# DISPC register map
Vendor: Texas Instruments
Registers are 32-bit, access per field, reset 0x0 unless marked. A register's access mark holds for its fields unless they carry their own. Offsets are as the file gives them; [hi:lo] are bit positions; {n}, {i} and the like mark numbered series; 'fields as' and 'values as' point back to an identical list.

## DISPC (part 6 of 6)
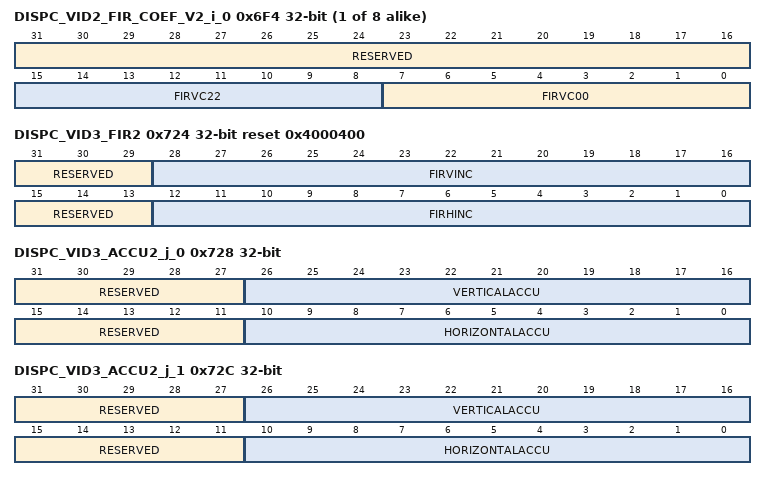
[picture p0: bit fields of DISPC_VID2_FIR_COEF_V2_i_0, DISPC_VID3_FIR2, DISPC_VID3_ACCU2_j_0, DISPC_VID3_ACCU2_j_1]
{0x6F4+4i} DISPC_VID2_FIR_COEF_V2_i_{i} (i=0..7) — The bank of registers configure the down/up/down-scaling coefficients for the vertical resize of the video picture associated with the video window 2 for the phases from 0 to 7. It is used for Crb and Cr setting. It is used only when the pixel format at the input of the filter is one of the YUV formats. If the pixel format at the input of the filter is ARGB (all ARGB, RGB, RGBA are converted to ARGB32-8888 by the color space conversion before going to the filter is the color space conversion is done before the filter). When the register is not used by the hardware, any value can be used for the bit fields. Shadow register, updated on VFP start period of primary LCD or VFP start period of the secondary LCD or VFP start period of the third LCD or EVSYNC or when.GOWB is set to 1 by software and current WB frame is finished (no more data in the write-back pipeline). The synchronization event is defined based on the output using the pipeline: primary LCD, secondary LCD, third LCD, TV output or write-back to the memory
  [31:16] RESERVED ro — Write 0s for future compatibility. Reads return 0.
  [15:8] FIRVC22 rw — Signed coefficient C22 for the vertical up/down-scaling with the phase n
  [7:0] FIRVC00 rw — Signed coefficient C00 for the vertical up/down-scaling with the phase n
0x724 DISPC_VID3_FIR2 reset 0x4000400 — The register configures the resize factors for horizontal and vertical up/downsampling of the video window 3. It is used for Crb and Cr setting. It is used only when the pixel format at the input of the filter is one of the YUV formats. If the pixel format at the input of the filter is ARGB (all ARGB, RGB, RGBA are converted to ARGB32-8888 by the color space conversion before going to the filter is the color space conversion is done before the filter). When the register is not used by the hardware, any value can be used for the bit fields. Shadow register, updated on VFP start period of primary LCD or VFP start period of the secondary LCD or VFP start period of the third LCD or EVSYNC or when.GOWB is set to 1 by software and current WB frame is finished (no more data in the write-back pipeline). The synchronization event is defined based on the output using the pipeline: primary LCD, secondary LCD, third LCD, TV output or write-back to the memory
  [31:29] RESERVED ro — Write 0s for future compatibility. Reads return 0.
  [28:16] FIRVINC rw — Vertical increment of the up/downsampling filter for Cb and Cr. Encoded value (from 1 to 4096). The value 0 is invalid. The values greater than 4096 are invalid.
  [15:13] RESERVED ro — Write 0s for future compatibility. Reads return 0.
  [12:0] FIRHINC rw — Horizontal increment of the up/downsampling filter for Cb and Cr. Encoded value (from 1 to 4096). The value 0 is invalid. The values greater than 4096 are invalid.
0x728 DISPC_VID3_ACCU2_j_0 — The register configures the resize accumulator init values for horizontal and vertical up/downsampling of the video window 3 (DISPC_VID3_ACCU2_0 and DISPC_VID3_ACCU2_1 for ping-pong mechanism with external trigger, based on the field polarity). It is used for Cb and Cr setting. It is used only when the pixel format at the input of the filter is one of the YUV formats. If the pixel format at the input of the filter is ARGB (all ARGB, RGB, RGBA are converted to ARGB32-8888 by the color space conversion before going to the filter is the color space conversion is done before the filter). When the register is not used by the hardware, any value can be used for the bit fields. Shadow register, updated on VFP start period of primary LCD or VFP start period of the secondary LCD or VFP start period of the third LCD or EVSYNC or when.GOWB is set to 1 by software and current WB frame is finished (no more data in the write-back pipeline). The synchronization event is defined based on the output using the pipeline: primary LCD, secondary LCD, third LCD, TV output or write-back to the memory
  [31:27] RESERVED ro — Write 0s for future compatibility. Reads return 0.
  [26:16] VERTICALACCU rw — Vertical initialization accu value Encoded value (from –1024 to 1023).
  [15:11] RESERVED ro — Write 0s for future compatibility. Reads return 0.
  [10:0] HORIZONTALACCU rw — Horizontal initialization accu value Encoded value (from –1024 to 1023).
0x72C DISPC_VID3_ACCU2_j_1 — The register configures the resize accumulator init values for horizontal and vertical up/downsampling of the video window 3 (DISPC_VID3_ACCU2_0 and DISPC_VID3_ACCU2_1 for ping-pong mechanism with external trigger, based on the field polarity). It is used for Cb and Cr setting. It is used only when the pixel format at the input of the filter is one of the YUV formats. If the pixel format at the input of the filter is ARGB (all ARGB, RGB, RGBA are converted to ARGB32-8888 by the color space conversion before going to the filter is the color space conversion is done before the filter). When the register is not used by the hardware, any value can be used for the bit fields. Shadow register, updated on VFP start period of primary LCD or VFP start period of the secondary LCD or VFP start period of the third LCD or EVSYNC or when.GOWB is set to 1 by software and current WB frame is finished (no more data in the write-back pipeline). The synchronization event is defined based on the output using the pipeline: primary LCD, secondary LCD, third LCD, TV output or write-back to the memory
  fields as DISPC_VID3_ACCU2_j_0
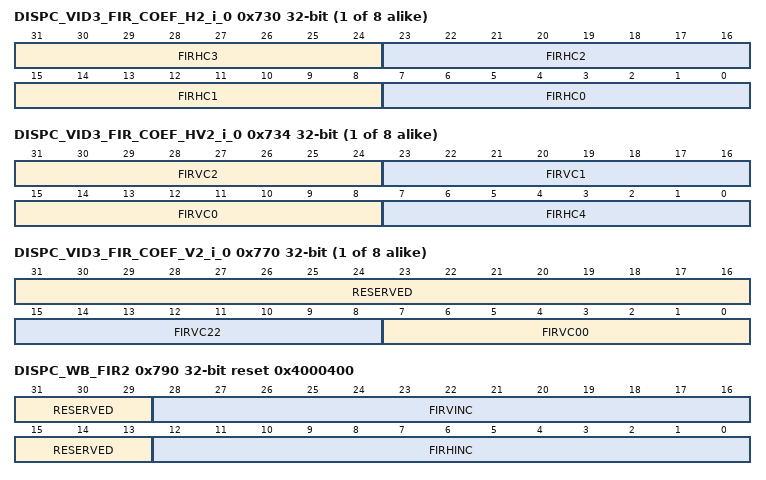
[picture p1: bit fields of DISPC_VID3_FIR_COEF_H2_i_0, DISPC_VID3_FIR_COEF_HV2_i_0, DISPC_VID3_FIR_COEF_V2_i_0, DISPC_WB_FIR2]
{0x730+8i} DISPC_VID3_FIR_COEF_H2_i_{i} rw (i=0..7) — The bank of registers configure the up/down-scaling coefficients for the horizontal resize of the video picture associated with the video window 3 for the phases from 0 to 7. It is used for Crb and Cr setting. It is used only when the pixel format at the input of the filter is one of the YUV formats. If the pixel format at the input of the filter is ARGB (all ARGB, RGB, RGBA are converted to ARGB32-8888 by the color space conversion before going to the filter is the color space conversion is done before the filter). When the register is not used by the hardware, any value can be used for the bit fields. Shadow register, updated on VFP start period of primary LCD or VFP start period of the secondary LCD or VFP start period of the third LCD or EVSYNC or when.GOWB is set to 1 by software and current WB frame is finished (no more data in the write-back pipeline). The synchronization event is defined based on the output using the pipeline: primary LCD, secondary LCD, third LCD, TV output or write-back to the memory
  [31:24] FIRHC3 — Signed coefficient C3 for the horizontal up/down-scaling with the phase n
  [23:16] FIRHC2 — Unsigned coefficient C2 for the horizontal up/down-scaling with the phase n
  [15:8] FIRHC1 — Signed coefficient C1 for the horizontal up/down-scaling with the phase n
  [7:0] FIRHC0 — Signed coefficient C0 for the horizontal up/down-scaling with the phase n
{0x734+8i} DISPC_VID3_FIR_COEF_HV2_i_{i} rw (i=0..7) — The bank of registers configure the down/up/down-scaling coefficients for the vertical and horizontal resize of the video picture associated with the video window 3 for the phases from 0 to 7. It is used for Crb and Cr setting. It is used only when the pixel format at the input of the filter is one of the YUV formats. If the pixel format at the input of the filter is ARGB (all ARGB, RGB, RGBA are converted to ARGB32-8888 by the color space conversion before going to the filter is the color space conversion is done before the filter). When the register is not used by the hardware, any value can be used for the bit fields. Shadow register, updated on VFP start period of primary LCD or VFP start period of the secondary LCD or VFP start period of the third LCD or EVSYNC or when.GOWB is set to 1 by software and current WB frame is finished (no more data in the write-back pipeline). The synchronization event is defined based on the output using the pipeline: primary LCD, secondary LCD, third LCD, TV output or write-back to the memory
  [31:24] FIRVC2 — Signed coefficient C2 for the vertical up/down-scaling with the phase n
  [23:16] FIRVC1 — Unsigned coefficient C1 for the vertical up/down-scaling with the phase n
  [15:8] FIRVC0 — Signed coefficient C0 for the vertical up/down-scaling with the phase n
  [7:0] FIRHC4 — Signed coefficient C4 for the horizontal up/down-scaling with the phase n
{0x770+4i} DISPC_VID3_FIR_COEF_V2_i_{i} (i=0..7) — The bank of registers configure the down/up/down-scaling coefficients for the vertical resize of the video picture associated with the video window 3 for the phases from 0 to 7. It is used for Crb and Cr setting. It is used only when the pixel format at the input of the filter is one of the YUV formats. If the pixel format at the input of the filter is ARGB (all ARGB, RGB, RGBA are converted to ARGB32-8888 by the color space conversion before going to the filter is the color space conversion is done before the filter). When the register is not used by the hardware, any value can be used for the bit fields. Shadow register, updated on VFP start period of primary LCD or VFP start period of the secondary LCD or VFP start period of the third LCD or EVSYNC or when.GOWB is set to 1 by software and current WB frame is finished (no more data in the write-back pipeline). The synchronization event is defined based on the output using the pipeline: primary LCD, secondary LCD, third LCD, TV output or write-back to the memory
  fields as DISPC_VID2_FIR_COEF_V2_i_0
0x790 DISPC_WB_FIR2 reset 0x4000400 — The register configures the resize factors for horizontal and vertical up/downsampling of the write-back pipeline. It is used for Crb and Cr setting. It is used only when the pixel format at the input of the filter is one of the YUV formats. If the pixel format at the input of the filter is ARGB (all ARGB, RGB, RGBA are converted to ARGB32-8888 by the color space conversion before going to the filter is the color space conversion is done before the filter). When the register is not used by the hardware, any value can be used for the bit fields. Shadow register, updated when.GOWB is set to 1 by software and current WB frame is finished (no more data in the write-back pipeline), when the WB pipeline is directly connected to one of the pipelines (graphics or video), combined with the synchronization event of the channel overlay output selected as an input to the WB pipeline (that is, VFP start period of primary LCD, or VFP start period of secondary LCD, or VFP start period of the third LCD, or EVSYNC), for all registers associated with the selected channel out and further delayed by the .WBDELAYCOUNT bit-field, for all registers of the Write back and DMA. In WB capture mode, both .GOWB and DISPC_CONTROL#.GOLCD/TV corresponding to the selected output channel shall be set. It is not required to set the GOWB bit when WB memory-to-memory mode is used.
  fields as DISPC_VID3_FIR2
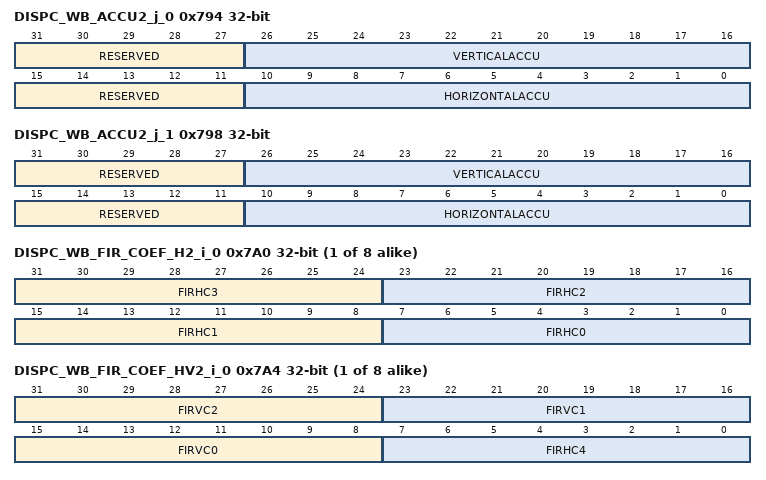
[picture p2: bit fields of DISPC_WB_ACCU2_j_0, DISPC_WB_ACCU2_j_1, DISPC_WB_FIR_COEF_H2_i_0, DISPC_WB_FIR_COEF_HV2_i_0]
0x794 DISPC_WB_ACCU2_j_0 — The register configures the resize accumulator init values for horizontal and vertical up/downsampling of the write back pipeline (DISPC_WB_ACCU2_0 and DISPC_WB_ACCU2_1 for ping-pong mechanism with external trigger, based on the field polarity). It is used for Cb and Cr setting. It is used only when the pixel format at the input of the filter is one of the YUV formats. If the pixel format at the input of the filter is ARGB (all ARGB, RGB, RGBA are converted to ARGB32-8888 by the color space conversion before going to the filter is the color space conversion is done before the filter). When the register is not used by the hardware, any value can be used for the bit fields. Shadow register, updated when.GOWB is set to 1 by software and current WB frame is finished (no more data in the write-back pipeline), when the WB pipeline is directly connected to one of the pipelines (graphics or video), combined with the synchronization event of the channel overlay output selected as an input to the WB pipeline (that is, VFP start period of primary LCD, or VFP start period of secondary LCD, or VFP start period of the third LCD, or EVSYNC), for all registers associated with the selected channel out and further delayed by the .WBDELAYCOUNT bit-field, for all registers of the Write back and DMA. In WB capture mode, both .GOWB and DISPC_CONTROL#.GOLCD/TV corresponding to the selected output channel shall be set. It is not required to set the GOWB bit when WB memory-to-memory mode is used.
  fields as DISPC_VID3_ACCU2_j_0
0x798 DISPC_WB_ACCU2_j_1 — The register configures the resize accumulator init values for horizontal and vertical up/downsampling of the write back pipeline (DISPC_WB_ACCU2_0 and DISPC_WB_ACCU2_1 for ping-pong mechanism with external trigger, based on the field polarity). It is used for Cb and Cr setting. It is used only when the pixel format at the input of the filter is one of the YUV formats. If the pixel format at the input of the filter is ARGB (all ARGB, RGB, RGBA are converted to ARGB32-8888 by the color space conversion before going to the filter is the color space conversion is done before the filter). When the register is not used by the hardware, any value can be used for the bit fields. Shadow register, updated when.GOWB is set to 1 by software and current WB frame is finished (no more data in the write-back pipeline), when the WB pipeline is directly connected to one of the pipelines (graphics or video), combined with the synchronization event of the channel overlay output selected as an input to the WB pipeline (that is, VFP start period of primary LCD, or VFP start period of secondary LCD, or VFP start period of the third LCD, or EVSYNC), for all registers associated with the selected channel out and further delayed by the .WBDELAYCOUNT bit-field, for all registers of the Write back and DMA. In WB capture mode, both .GOWB and DISPC_CONTROL#.GOLCD/TV corresponding to the selected output channel shall be set. It is not required to set the GOWB bit when WB memory-to-memory mode is used.
  fields as DISPC_VID3_ACCU2_j_0
{0x7A0+8i} DISPC_WB_FIR_COEF_H2_i_{i} rw (i=0..7) — The bank of registers configure the up/down-scaling coefficients for the horizontal resize of the video picture associated with the write back pipeline for the phases from 0 to 7. It is used for Crb and Cr setting. It is used only when the pixel format at the input of the filter is one of the YUV formats. If the pixel format at the input of the filter is ARGB (all ARGB, RGB, RGBA are converted to ARGB32-8888 by the color space conversion before going to the filter is the color space conversion is done before the filter). When the register is not used by the hardware, any value can be used for the bit fields. Shadow register, updated when.GOWB is set to 1 by software and current WB frame is finished (no more data in the write-back pipeline), when the WB pipeline is directly connected to one of the pipelines (graphics or video), combined with the synchronization event of the channel overlay output selected as an input to the WB pipeline (that is, VFP start period of primary LCD, or VFP start period of secondary LCD, or VFP start period of the third LCD, or EVSYNC), for all registers associated with the selected channel out and further delayed by the .WBDELAYCOUNT bit-field, for all registers of the Write back and DMA. In WB capture mode, both .GOWB and DISPC_CONTROL#.GOLCD/TV corresponding to the selected output channel shall be set. It is not required to set the GOWB bit when WB memory-to-memory mode is used.
  fields as DISPC_VID3_FIR_COEF_H2_i_0
{0x7A4+8i} DISPC_WB_FIR_COEF_HV2_i_{i} rw (i=0..7) — The bank of registers configure the down/up/down-scaling coefficients for the vertical and horizontal resize of the video picture associated with the write back pipeline for the phases from 0 to 7. It is used for Crb and Cr setting. It is used only when the pixel format at the input of the filter is one of the YUV formats. If the pixel format at the input of the filter is ARGB (all ARGB, RGB, RGBA are converted to ARGB32-8888 by the color space conversion before going to the filter is the color space conversion is done before the filter). When the register is not used by the hardware, any value can be used for the bit fields. Shadow register, updated when.GOWB is set to 1 by software and current WB frame is finished (no more data in the write-back pipeline), when the WB pipeline is directly connected to one of the pipelines (graphics or video), combined with the synchronization event of the channel overlay output selected as an input to the WB pipeline (that is, VFP start period of primary LCD, or VFP start period of secondary LCD, or VFP start period of the third LCD, or EVSYNC), for all registers associated with the selected channel out and further delayed by the .WBDELAYCOUNT bit-field, for all registers of the Write back and DMA. In WB capture mode, both .GOWB and DISPC_CONTROL#.GOLCD/TV corresponding to the selected output channel shall be set. It is not required to set the GOWB bit when WB memory-to-memory mode is used.
  fields as DISPC_VID3_FIR_COEF_HV2_i_0
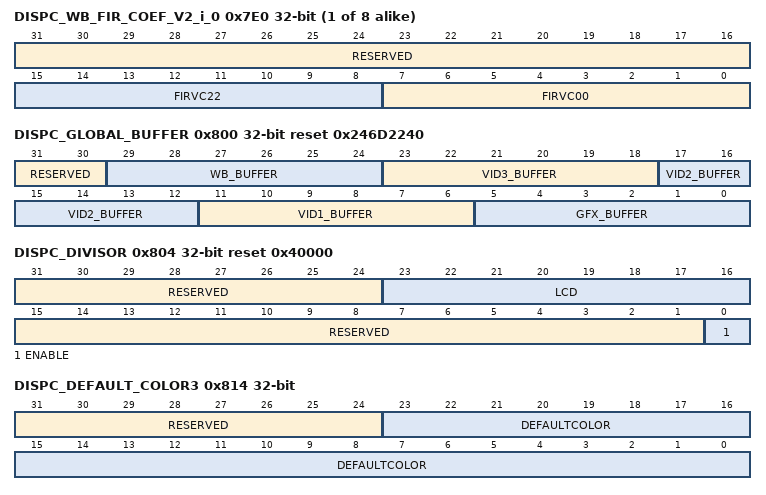
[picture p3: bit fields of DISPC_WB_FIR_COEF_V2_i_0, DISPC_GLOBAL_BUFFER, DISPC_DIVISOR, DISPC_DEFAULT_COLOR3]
{0x7E0+4i} DISPC_WB_FIR_COEF_V2_i_{i} (i=0..7) — The bank of registers configure the down/up/down-scaling coefficients for the vertical resize of the video picture associated with the write back pipeline for the phases from 0 to 7. It is used for Crb and Cr setting. It is used only when the pixel format at the input of the filter is one of the YUV formats. If the pixel format at the input of the filter is ARGB (all ARGB, RGB, RGBA are converted to ARGB32-8888 by the color space conversion before going to the filter is the color space conversion is done before the filter). When the register is not used by the hardware, any value can be used for the bit fields. Shadow register, updated when.GOWB is set to 1 by software and current WB frame is finished (no more data in the write-back pipeline), when the WB pipeline is directly connected to one of the pipelines (graphics or video), combined with the synchronization event of the channel overlay output selected as an input to the WB pipeline (that is, VFP start period of primary LCD, or VFP start period of secondary LCD, or VFP start period of the third LCD, or EVSYNC), for all registers associated with the selected channel out and further delayed by the .WBDELAYCOUNT bit-field, for all registers of the Write back and DMA. In WB capture mode, both .GOWB and DISPC_CONTROL#.GOLCD/TV corresponding to the selected output channel shall be set. It is not required to set the GOWB bit when WB memory-to-memory mode is used.
  fields as DISPC_VID2_FIR_COEF_V2_i_0
0x800 DISPC_GLOBAL_BUFFER reset 0x246D2240 — The register configures the DMA buffers allocations to the pipeline (graphics, video1, video2, video3 and write-back). Both TOP and BOTTOM must be allocated to the same pipeline.
  [31:30] RESERVED ro — Write 0's for future compatibility. Reads return 0
  [29:24] WB_BUFFER rw — Write-back DMA buffer allocation to one of the pipelines. By default to write-back pipeline.
    36=Wb (DMA buffer allocated to the write-back pipeline.); 0=Gfx (DMA buffer allocated to the graphics pipeline.); 9=Vid1 (DMA buffer allocated to the video1 pipeline.); 18=Vid2 (DMA buffer allocated to the vdieo2 pipeline.); 27=Vid3 (DMA buffer allocated to the vdieo3 pipeline.)
  [23:18] VID3_BUFFER rw — Video3 DMA buffer allocation to one of the pipelines. By default to video3 pipeline.
    values as WB_BUFFER
  [17:12] VID2_BUFFER rw — Video2 DMA buffer allocation to one of the pipelines. By default to video2 pipeline.
    values as WB_BUFFER
  [11:6] VID1_BUFFER rw — Video1 DMA buffer allocation to one of the pipelines. By default to video 1 pipeline.
    values as WB_BUFFER
  [5:0] GFX_BUFFER rw — Graphics DMA buffer allocation to one of the pipelines. By default to graphics pipeline.
    values as WB_BUFFER
0x804 DISPC_DIVISOR reset 0x40000 — The register configures the divisor value for generating the core functional clock. There is a backward compatibility mode enabled by default in order to use.LCD value instead of .LCD bit field for generating the core functional clock.
  [31:24] RESERVED ro — Write 0s for future compatibility. Reads return 0.
  [23:16] LCD rw — Display Controller Logic Clock Divisor Value (from 1 to 255) to specify the frequency of the Display Controller logic clock based on the function clock. The value 0 is invalid.
  [15:1] RESERVED ro — Write 0s for future compatibility. Reads return 0.
  [0] ENABLE rw — When the bit field is set to 1, the bit field LCD is used to generated the core functional clock from the input clock. When the bit field is set to 0, the valueDISPC_DIVISOR1.LCD is used instead.
    0=Disable (.LCD bit field is used); 1=Enable (.LCD bit field is used)
0x810 DISPC_WB_ATTRIBUTES2 — The register set the counter to control the delay to flush the WB pipe after the end of the frame in capture mode. Shadow register, updated when .GOWB is set to 1 by software and current WB frame is finished (no more data in the write-back pipeline), when the WB pipeline is directly connected to one of the pipelines (graphics or video), combined with the synchronization event of the channel overlay output selected as an input to the WB pipeline (that is, VFP start period of primary LCD, or VFP start period of secondary LCD, or VFP start period of the third LCD, or EVSYNC), for all registers associated with the selected channel out and further delayed by the .WBDELAYCOUNT bit-field, for all registers of the Write back and DMA. In WB capture mode, both .GOWB and DISPC_CONTROL#.GOLCD/TV corresponding to the selected output channel shall be set. It is not required to set the GOWB bit when WB memory-to-memory mode is used.
  [7:0] WBDELAYCOUNT rw — Delays the WB pipe flush after the end of the frame. Delay = n (number of lines), where n = 0:255. If n = 0, the WB is re-initialized just at the end of the last line of a frame at the beginning of the VFP signal. If n = 1:255, the write buffers DMA are flushed n lines later.
0x814 DISPC_DEFAULT_COLOR3 — The control register allows to configure the default solid background color for the third LCD. Shadow register, updated on VFP start period of third LCD
  [31:24] RESERVED ro — Write 0s for future compatibility. Reads return 0.
  [23:0] DEFAULTCOLOR rw — 24-bit RGB color value to specify the default solid color to display when there is no data from the overlays
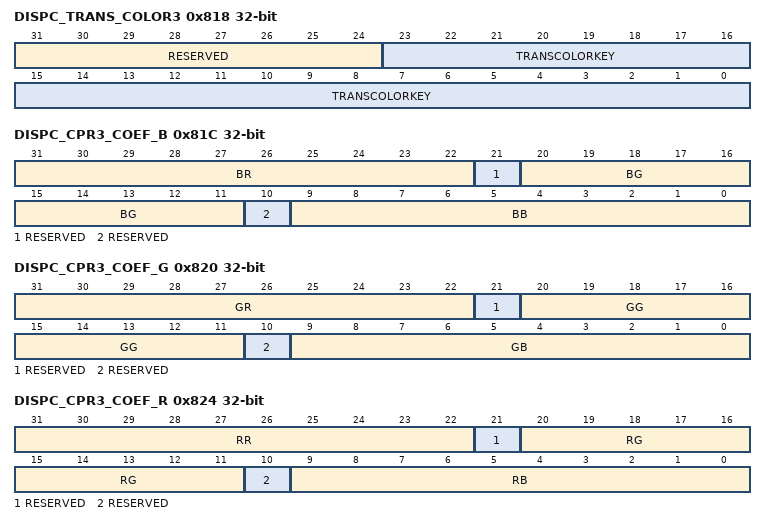
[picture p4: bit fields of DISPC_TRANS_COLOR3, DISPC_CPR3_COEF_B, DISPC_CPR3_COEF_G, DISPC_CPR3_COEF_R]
0x818 DISPC_TRANS_COLOR3 — The register sets the transparency color value for the video/graphics overlays for the third LCD output. Shadow register, updated on VFP start period of the third LCD
  [31:24] RESERVED ro — Write 0s for future compatibility. Reads return 0.
  [23:0] TRANSCOLORKEY rw — Transparency color key value in RGB format [0] BITMAP 1 (CLUT), [23,1] set to 0s [1:0] BITMAP 2 (CLUT), [23,2] set to 0s [3:0] BITMAP 4 (CLUT), [23,4] set to 0s [7:0] BITMAP 8 (CLUT), [23,8] set to 0s [11:0] RGB 12, [23,12] set to 0s [15:0] RGB 16, [23,16] set to 0s [23:0] RGB 24 NOTE: CLUT and BITMAP formats are not supported in this family of devices.
0x81C DISPC_CPR3_COEF_B — The register configures the color phase rotation matrix coefficients for the blue component. It is used for the secondary LCD output. Shadow register, updated on VFP start period of third LCD
  [31:22] BR rw — BR coefficient Encoded signed value (from –512 to 511)
  [21] RESERVED ro — Write 0s for future compatibility. Reads return 0.
  [20:11] BG rw — BG coefficient Encoded signed value (from –512 to 511)
  [10] RESERVED ro — Write 0s for future compatibility. Reads return 0.
  [9:0] BB rw — BB coefficient Encoded signed value (from –512 to 511)
0x820 DISPC_CPR3_COEF_G — The register configures the color phase rotation matrix coefficients for the green component. It is used for the secondary LCD output. Shadow register, updated on VFP start period of third LCD
  [31:22] GR rw — GRcoefficient Encoded signed value (from –512 to 511)
  [21] RESERVED ro — Write 0s for future compatibility. Reads return 0.
  [20:11] GG rw — GG coefficient Encoded signed value (from –512 to 511)
  [10] RESERVED ro — Write 0s for future compatibility. Reads return 0.
  [9:0] GB rw — GB coefficient Encoded signed value (from –512 to 511)
0x824 DISPC_CPR3_COEF_R — The register configures the color phase rotation matrix coefficients for the red component. Shadow register, updated on VFP start period of third LCD
  [31:22] RR rw — RR coefficient Encoded signed value (from –512 to 511)
  [21] RESERVED ro — Write 0s for future compatibility. Reads return 0.
  [20:11] RG rw — RG coefficient Encoded signed value (from –512 to 511)
  [10] RESERVED ro — Write 0s for future compatibility. Reads return 0.
  [9:0] RB rw — RB coefficient Encoded signed value (from –512 to 511)
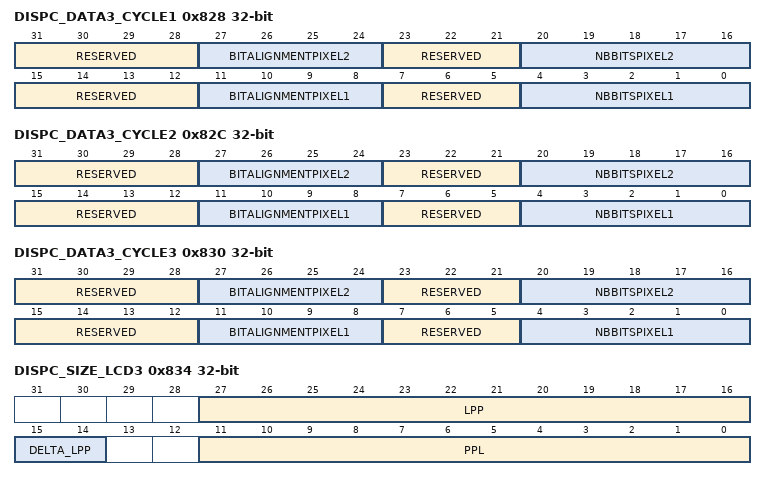
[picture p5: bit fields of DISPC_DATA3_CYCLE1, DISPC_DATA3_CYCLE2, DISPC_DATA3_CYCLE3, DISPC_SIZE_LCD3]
0x828 DISPC_DATA3_CYCLE1 — The control register configures the output data format for the first cycle. Shadow register, updated on VFP start period of third LCD
  [31:28] RESERVED ro — Write 0s for future compatibility. Reads return 0.
  [27:24] BITALIGNMENTPIXEL2 rw — Bit alignment Alignment of the bits from pixel 2 on the output interface
  [23:21] RESERVED ro — Write 0s for future compatibility. Reads return 0.
  [20:16] NBBITSPIXEL2 rw — Number of bits Number of bits from the pixel 2 (value from 0 to 16 bits). The values from 17 to 31 are invalid.
  [15:12] RESERVED ro — Write 0s for future compatibility. Reads return 0.
  [11:8] BITALIGNMENTPIXEL1 rw — Bit alignment Alignment of the bits from pixel 1 on the output interface
  [7:5] RESERVED ro — Write 0s for future compatibility. Reads return 0.
  [4:0] NBBITSPIXEL1 rw — Number of bits Number of bits from the pixel 1 (value from 0 to 16 bits). The values from 17 to 31 are invalid.
0x82C DISPC_DATA3_CYCLE2 — The control register configures the output data format for the second cycle. Shadow register, updated on VFP start period of third LCD
  fields as DISPC_DATA3_CYCLE1
0x830 DISPC_DATA3_CYCLE3 — The control register configures the output data format for the third cycle. Shadow register, updated on VFP start period of third LCD
  fields as DISPC_DATA3_CYCLE1
0x834 DISPC_SIZE_LCD3 — The register configures the panel size (horizontal and vertical). It is used for the third LCD output. Shadow register, updated on VFP start period of the third LCD. A delta value is used to indicate if the odd field is the same vertical size as the even field or ± one line.
  [27:16] LPP rw — Lines per panel Encoded value (from 1 to 4096) to specify the number of lines per panel (program to value minus 1).
  [15:14] DELTA_LPP rw — Indicates the delta size value of the odd field compared to the even field
    0=Same size; 1=PlusOne (Odd size = even size +1); 2=MinusOne (Odd size = even size –1)
  [11:0] PPL rw — Pixels per line Encoded value (from 1 to 4096) to specify the number of pixels contained within each line on the display (program to value minus 1). In STALL mode, any value is valid. In non-STALL mode, only values of multiples of 8 pixels are valiid.
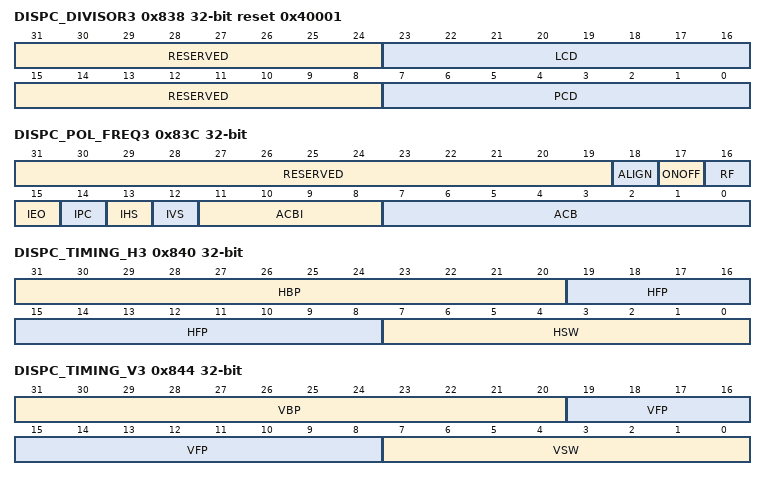
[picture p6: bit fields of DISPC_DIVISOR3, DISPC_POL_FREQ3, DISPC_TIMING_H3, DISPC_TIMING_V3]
0x838 DISPC_DIVISOR3 reset 0x40001 — The register configures the divisors. It is used for the third LCD output. Shadow register, updated on VFP start period of the third LCD
  [31:24] RESERVED ro — Write 0s for future compatibility. Reads return 0.
  [23:16] LCD rw — Display controller logic clock divisor Value (from 1 to 255) to specify the intermediate pixel clock frequency based on LCD2_CLK. The value 0 is invalid.
  [15:8] RESERVED ro — Write 0s for future compatibility. Reads return 0.
  [7:0] PCD rw — Pixel clock divisor Value (from 1 to 255) to specify the frequency of the pixel clock based on LCD2_CLK divided by the value of DISPC_DIVISOR2.LCD. The value 0 is invalid.
0x83C DISPC_POL_FREQ3 — The register configures the signal configuration. It is used for the third LCD output. Shadow register, updated on VFP start period of the third LCD
  [31:19] RESERVED ro — Write 0s for future compatibility. Reads return 0.
  [18] ALIGN rw — Defines the alignment betwwen HSYNC and VSYNC assertion
    0=notAligned (VSYNC and HSYNC are not aligned.); 1=Aligned (VSYNC and HSYNC assertions are aligned.)
  [17] ONOFF rw — HSYNC/VSYNC pixel clock control on/offNote: Control module register CTRL_CORE_SMA_SW_1[24] DSS_CH2_ON_OFF must be set to match enum=DBit16 .
    0=DOpEdPCk (HSYNC and VSYNC are driven on opposite edges of the pixel clock than pixel data.); 1=DBit16 (HSYNC and VSYNC are driven according to bit 16.)
  [16] RF rw — Program HSYNC/VSYNC rise or fallNote: Control module register CTRL_CORE_SMA_SW_1[18] DSS_CH2_RF must be set to match enum=DRiEdPCk .
    0=DFEdPCk (HSYNC and VSYNC are driven on the falling edge of the pixel clock (if bit 17 is set to 1).); 1=DRiEdPCk (HSYNC and VSYNC are driven onthe rising edge of the pixel clock (if bit 17 is set to 1).)
  [15] IEO rw — Invert output enable
    0=ACBaHigh (Ac-bias is active high (active display mode).); 1=ACBaLow (Ac-bias is active low (active display mode).)
  [14] IPC rw — Invert pixel clockNote: Control module register CTRL_CORE_SMA_SW_1[21] DSS_CH2_IPC must be set to match enum=DfPCk .
    0=DrPCk (Data is driven on the LCD data lines on the rising edge of the pixel clock.); 1=DfPCk (Data is driven on the LCD data lines on the falling edge of the pixel clock.)
  [13] IHS rw — Invert HSYNC
    0=LCkpinAh (Line clock pin is active high and inactive low.); 1=LCkpinAl (Line clock pin is active low and inactive high.)
  [12] IVS rw — Invert VSYNC
    0=FCkpinAh (Frame clock pin is active high and inactive low.); 1=FCkpinAl (Frame clock pin is active low and inactive high.)
  [11:8] ACBI rw — AC bias pin transitions per interrupt Value (from 0 to 15) used to specify the number of AC bias pin transitions
  [7:0] ACB rw — AC bias pin frequency Value (from 0 to 255) used to specify the number of line clocks to count before transitioning the AC bias pin. This pin is used to periodically invert the polarity of the power supply to prevent DC charge buildup within the display.
0x840 DISPC_TIMING_H3 rw — The register configures the timing logic for the HSYNC signal. It is used for the third LCD output. Shadow register, updated on VFP start period of the third LCD
  [31:20] HBP — Horizontal back porch. Encoded value (from 1 to 4096) to specify the number of pixel clock periods to add to the beginning of a line transmission before the first set of pixels is output to the display (program to value minus 1).
  [19:8] HFP — Horizontal front porch. Encoded value (from 1 to 4096) to specify the number of pixel clock periods to add to the end of a line transmission before the line clock is asserted (program to value minus 1).
  [7:0] HSW — Horizontal synchronization pulse width. Encoded value (from 1 to 256) to specify the number of pixel clock periods to pulse the line clock at the end of each line (program to value minus 1).
0x844 DISPC_TIMING_V3 rw — The register configures the timing logic for the VSYNC signal. It is used for the third LCD output. Shadow register, updated on VFP start period of the third LCD
  [31:20] VBP — Vertical back porch. Encoded value (from 0 to 4095) to specify the number of line clock periods to add to the beginning of a frame before the first set of pixels is output to the display
  [19:8] VFP — Vertical front porch. Encoded value (from 0 to 4095) to specify the number of line clock periods to add to the end of each frame
  [7:0] VSW — Vertical synchronization pulse width. In active mode, encoded value (from 1 to 256) to specify the number of line clock periods (program to value minus 1) to pulse the frame clock (VSYNC) pin at the end of each frame after the end of frame wait (VFP) period elapses. Frame clock uses as VSYNC signal in active mode.
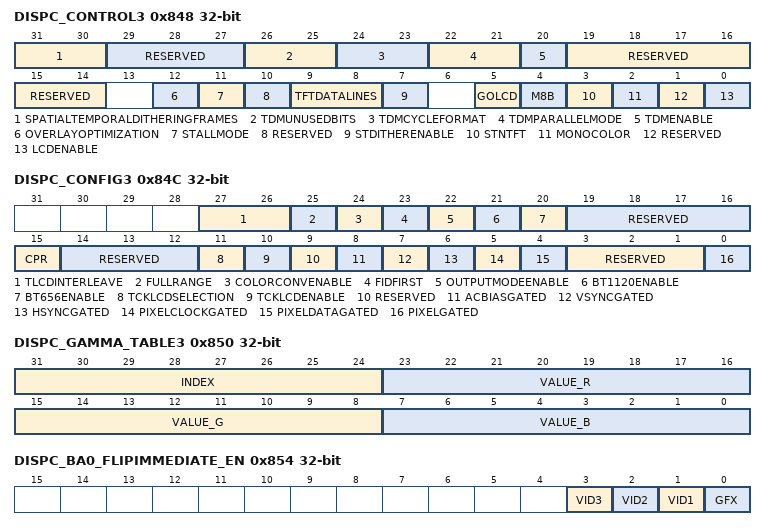
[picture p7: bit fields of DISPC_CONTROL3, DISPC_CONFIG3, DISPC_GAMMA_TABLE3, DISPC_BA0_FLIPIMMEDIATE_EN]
0x848 DISPC_CONTROL3 — The control register configures the display controller module for the third LCD output.
  [31:30] SPATIALTEMPORALDITHERINGFRAMES rw — Spatial/temporal dithering number of frames for the third LCD output wr: VFP start period of the third LCD output
    0=OneFrame (Spatial only); 1=TwoFrames (Spatial and temporal over two frames); 2=FourFrames (Spatial and temporal over four frames)
  [29:27] RESERVED ro — Write 0s for future compatibility. Reads return 0.
  [26:25] TDMUNUSEDBITS rw — State of unused bits (TDM mode only) for the third LCD output wr: VFP start period of the third LCD output
    0=Low level (0); 1=High level (1); 2=Unchanged from previous state
  [24:23] TDMCYCLEFORMAT rw — Cycle format (TDM mode only) for the third LCD output wr: VFP start period of third LCD output
    0=1CycPerPix (One cycle for 1 pixel); 1=2CycPerPix (Two cycles for 1 pixel); 3=3CycPer2Pix (Three cycles for 2 pixels); 2=3CycPerPix (Three cycles for 1 pixel)
  [22:21] TDMPARALLELMODE rw — Output interface width (TDM mode only) for the third LCD output wr: VFP start period of the third LCD output
    0=8bParaInt (8-bit parallel output interface selected); 1=9bParaInt (9-bit parallel output interface selected); 3=16bParaInt (16-bit parallel output interface selected); 2=12bParaInt (12-bit parallel output interface selected)
  [20] TDMENABLE rw — Enable the multiple cycle format for the third LCD output wr: VFP start period of third LCD output
    0=TDM disabled; 1=TDMEnb (TDM enabled)
  [19:14] RESERVED rw — Write 0s for future compatibility. Reads return 0.
  [12] OVERLAYOPTIMIZATION rw — Overlay optimization for the third LCD output wr: VFP or EVSYNC or when DISPC_CONTROL2.GOWB is set to 1 by software and current WB frame is finished (no more data in the write-back pipeline). The synchronization event is defined based on the output using the pipeline: primary LCD, secondary LCD, third LCD, TV output, or write-back to the memory.
    0=GDBVWfM (All the data for all the enabled pipelines are fetched from memory regardless of the overlay/alpha blending configuration.); 1=GDBVWnfM (The data not used by the overlay manager because of overlap between layers with no alpha blending between them must not be fetched from memory to optimize the bandwidth.)
  [11] STALLMODE rw — STALL mode for the third LCD output wr: VFP start period of the third LCD output
    0=nMode (Normal mode selected); 1=RFBIMode (STALL mode selected. The display controller sends the data without considering the VSYNC/HSYNC. The LCD output is disabled at the end of the transfer of the frame. Software must reenable the LCD output to generate a new frame.)
  [10] RESERVED ro — Write 0s for future compatibility. Reads return 0.
  [9:8] TFTDATALINES rw — Number of lines of the third LCD interface wr: VFP start period of the third LCD output
    0=OaLSB12b (12-bit output aligned on the LSB of the pixel data interface); 1=OaLSB16b (16-bit output aligned on the LSB of the pixel data interface); 3=OaLSB24b (24-bit output aligned on the LSB of the pixel data interface); 2=OaLSB18b (18-bit output aligned on the LSB of the pixel data interface)
  [7] STDITHERENABLE rw — Spatial temporal dithering enable for the third LCD output wr: VFP start period of the third LCD output
    0=STDithDis (Spatial/temporal dithering logic disabled); 1=STDithEnb (Spatial/temporal dithering logic enabled)
  [5] GOLCD rw — GO command for the third LCD output. It is used to synchronized the pipelines (graphics and/or video) associated with the third LCD output. wr: Immediate
    0=HfUISR (The hardware has finished updating the internal shadow registers of the pipeline(s) connected to the LCD output using the user values. The hardware resets the bit when the update is complete.); 1=UfPSR (The user has finished programming the shadow registers of the pipeline(s) associated with the LCD output, and the hardware can update the internal registers at the VFP start period.)
  [4] M8B rw — Mono 8-bit mode of the third LCD wr: VFP start period of the third LCD output
    0=4PixtoPanel (Reserved); 1=8PixtoPanel (Reserved)
  [3] STNTFT rw — LCD Display type of the third LCD wr: VFP start period of the third LCD output
    0=STNdispEnb (Reserved); 1=ATFTDisEnb (Active matrix display operation enabled)
  [2] MONOCOLOR rw — Monochrome/color selection for the third LCD wr: VFP start period of the third LCD output
    0=ColOpEnb (Reserved); 1=MonOpEnb (Reserved)
  [1] RESERVED ro — Write 0s for future compatibility. Reads return 0.
  [0] LCDENABLE rw — Enable the third LCD output wr: Immediate
    0=LCDOpDis (LCD output disabled (at the end of the frame when the bit is reset)); 1=LCDOpEnb (LCD output enabled)
0x84C DISPC_CONFIG3 — The control register configures the display controller module for the third LCD output. Shadow register, updated on VFP start period of the third LCD or EVSYNC
  [27:26] TLCDINTERLEAVE rw — tLCD interleave Pattern
  [25] FULLRANGE rw — Color space conversion full range setting
    0=Limrange (Limited range selected); 1=Full range selected
  [24] COLORCONVENABLE rw — Enable the color space conversion. It must be reset when the CPR bit field is set to 0x1.
    0=ColSpCDis (Disable color space conversion RGB to YUV.); 1=ColSpCEnb (Enable color space conversion RGB to YUV.)
  [23] FIDFIRST rw — Selects the first field to output in case of interlace mode. In case of progressive mode, the value is not used.
    0=Even (First field is even.); 1=Odd (Odd field is first.)
  [22] OUTPUTMODEENABLE rw — Selects between progressive and interlace mode for the third LCD output
    0=Disable (Progressive mode selected); 1=Enable (Interlace mode selected)
  [21] BT1120ENABLE rw — Selects BT.1120 format on the third LCD output. It is not posssible to enable BT.656 and BT.1120 at the same time on the same LCD output.
    0=Disable (BT.1120 is disabled.); 1=Enable (BT.1120 is enabled.)
  [20] BT656ENABLE rw — Selects BT.656 format on the third LCD output. It is not posssible to enable BT.656 and BT.1120 at the same time on the same LCD output.
    0=Disable (BT.656 is disabled.); 1=Enable (BT.656 is enabled.)
  [19:16] RESERVED ro — Write 0s for future compatibility. Reads return 0.
  [15] CPR rw — Color phase rotation control ( third LCD output). It must be reset when the ColorConvEnable bit field is set to 1. wr: VFP start period of the third LCD output
    0=CPRDis (Color phase rotation disabled); 1=CPREnb (Color phase rotation enabled)
  [14:12] RESERVED ro — Write 0s for future compatibility. Reads return 0.
  [11] TCKLCDSELECTION rw — Transparency color key selection (third LCD output) wr: VFP start period of the third LCD output
    0=GDTK (Destination transparency color key selected); 1=VSTK (Source transparency color key selected)
  [10] TCKLCDENABLE rw — Transparency color key enabled (third LCD output) wr: VFP start period of the third LCD output
    0=DisTCK (Disable the transparency color key for the LCD); 1=EnbTCK (Enable the transparency color key for the LCD)
  [9] RESERVED ro — Write 0s for future compatibility. Reads return 0.
  [8] ACBIASGATED rw — ACBias gated enabled (third LCD output) wr: VFP start period of the third LCD output
    0=ACBGDis (AcBias gated disabled); 1=ACBGEnb (AcBias gated enabled)
  [7] VSYNCGATED rw — VSYNC gated enabled (third LCD output) wr: VFP start period of the third LCD output
    0=VGDis (VSYNC gated disabled); 1=VGEnb (VSYNC gated enabled)
  [6] HSYNCGATED rw — HSYNC gated enabled (third LCD output) wr: VFP start period of the third LCD output
    0=HGDis (HSYNC gated disabled); 1=HGEnb (HSYNC gated enabled)
  [5] PIXELCLOCKGATED rw — Pixel clock gated enabled (third LCD output) wr: VFP start period of the third LCD output
    0=PCGDis (Pixel clock gated disabled); 1=PCGEnb (Pixel clock gated enabled)
  [4] PIXELDATAGATED rw — Pixel data gated enabled (third LCD output) wr: VFP start period of the third LCD output
    0=PDGDis (Pixel data gated disabled); 1=PDGEnb (Pixel data gated enabled)
  [3:1] RESERVED ro — Write 0s for future compatibility. Reads return 0.
  [0] PIXELGATED rw — Pixel gated enable (only for TFT) (third LCD output) wr: VFP start period of the third LCD output
    0=PclkTogA (Pixel clock always toggles (only in TFT mode).); 1=PclkTogV (Pixel clock toggles only when there is valid data to display (only in TFT mode).)
0x850 DISPC_GAMMA_TABLE3 wo — The register configures the gamma table on the third LCD output.
  [31:24] INDEX — Defines the location in the table where the VALUE bit field is stored.
  [23:16] VALUE_R — 8-bit value used to define the value to store at the location in the table defined by the INDEX bit field
  [15:8] VALUE_G — 8-bit value used to define the value to store at the location in the table defined by the INDEX bit field
  [7:0] VALUE_B — 8-bit value used to define the value to store at the location in the table defined by the INDEX bit field
0x854 DISPC_BA0_FLIPIMMEDIATE_EN — This register enables the flip immediate.
  [3] VID3 rw — Enable flip immediate for video3 pipeline
  [2] VID2 rw — Enable flip immediate for video2 pipeline
  [1] VID1 rw — Enable flip immediate for video1 pipeline
  [0] GFX rw — Enable flip immediate for gfx pipeline
0x858 DISABLE_MSTANDBY_ENHANCEMENT — This register disables the DISPC DMA Mstandby behavior enhancement.
  [0] DISABLE_MSTANDBY_ENHANCEMENT rw — 0: DISPC DMA Mstandby behavior enhancement is enabled. 1: Disable DISPC DMA Mstandby behavior enhancement. This is the recommended setting.
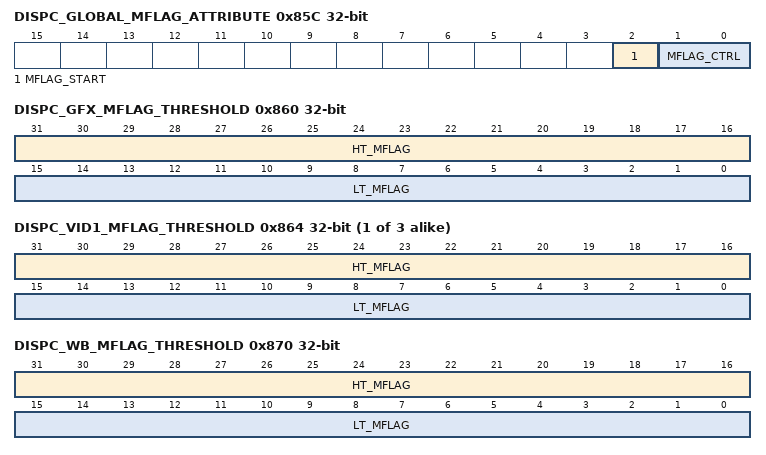
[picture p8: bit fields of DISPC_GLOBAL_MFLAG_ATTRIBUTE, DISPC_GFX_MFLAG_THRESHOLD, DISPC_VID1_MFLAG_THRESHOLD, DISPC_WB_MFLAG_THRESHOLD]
0x85C DISPC_GLOBAL_MFLAG_ATTRIBUTE — Global MFLAG atrribute control register.
  [2] MFLAG_START rw
    0=Inactive (When the DMA buffer is empty at the beginning of the frame, MFLAG signal of each pipeline is kept at 0 until PRELOAD is reached, then based on MFLAG_CTRL bitfield MFLAG is generated and internal logic is arbitrating between pipeline requests); 1=Active (Even at the beginning of the frame when the DMA buffer is empty, MFLAG_CTRL bitfield is used to determine how MFLAG signal for each pipeline shall be driven.)
  [1:0] MFLAG_CTRL rw — MFLAG control
    0=MFLAG_Dis (MFLAG mechanism is disabled: MFLAG out of band signal is set to 0); 1=MFLAG_Force (MFLAG mechanism is enabled: MFLAG out of band signal is always set to 1 (force mode for debug)); 2=MFLAG_En (MFLAG mechanism is enabled and MFLAG out of band signal is dynamically set and reset depending on MFLAG rules.)
0x860 DISPC_GFX_MFLAG_THRESHOLD rw — MFLAG thresholds for graphics pipeline. Shadow register, updated on VFP start period of primary LCD or VFP start period of the secondary LCD or external VSYNC or when.GOWB is set to 1 by software and current WB frame is finished (no more data in the write-back pipeline). The synchronization event is defined based on the output using the pipeline: primary LCD, secondary LCD, TV output or write-back to the memory.
  [31:16] HT_MFLAG — High Thresholds (in 128bits) for MFLAG generation: when FIFO fullness reaches HT_MFLAG level, MFLAG is reset to 0
  [15:0] LT_MFLAG — Low Thresholds (in 128bits) for MFLAG generation: when FIFO fullness reaches LT_MFLAG level, MFLAG is set to 1
{0x860+4i} DISPC_VID{i}_MFLAG_THRESHOLD rw (i=1..3) — MFLAG thresholds for video{i} pipeline. Shadow register, updated on VFP start period of primary LCD or VFP start period of the secondary LCD or external VSYNC or when.GOWB is set to 1 by software and current WB frame is finished (no more data in the write-back pipeline). The synchronization event is defined based on the output using the pipeline: primary LCD, secondary LCD, TV output or write-back to the memory.
  fields as DISPC_GFX_MFLAG_THRESHOLD
0x870 DISPC_WB_MFLAG_THRESHOLD rw — MFLAG thresholds for write-back pipeline. Shadow register, updated when.GOWB is set to 1 by software and current WB frame is finished (no more data in the write-back pipeline), when the WB pipeline is directly connected to one of the pipelines (graphics or video), combined with the synchronization event of the channel overlay output selected as an input to the WB pipeline (that is, VFP start period of primary LCD, or VFP start period of secondary LCD, or VFP start period of the third LCD, or EVSYNC), for all registers associated with the selected channel out and further delayed by the .WBDELAYCOUNT bit-field, for all registers of the Write back and DMA. In WB capture mode, both .GOWB and DISPC_CONTROL#.GOLCD/TV corresponding to the selected output channel shall be set. It is not required to set the GOWB bit when WB memory-to-memory mode is used.
  fields as DISPC_GFX_MFLAG_THRESHOLD
